# MDR32F8 register map
Vendor: Milandr; File version: 1.0
CPU: CM4 r1p1, little endian, no MPU, no FPU, 3 interrupt priority bits
Registers are 32-bit, read-write, reset 0x0 unless marked. A register's access mark holds for its fields unless they carry their own. Offsets are from the block's base; [hi:lo] are bit positions; {n}, {i} and the like mark numbered series.

## MDR_SSP — SSP interfase controller registers
Base 0x40095000; register names take the prefix MDR_SSP
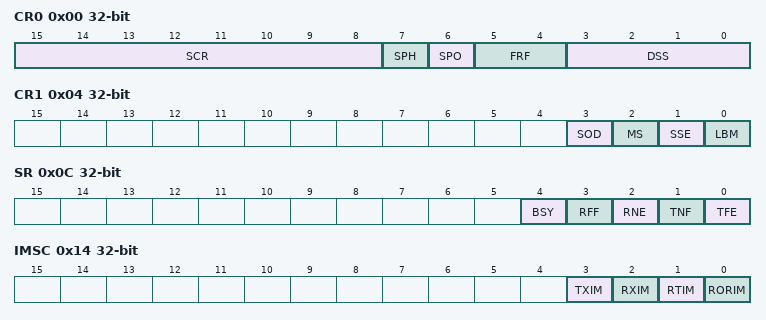
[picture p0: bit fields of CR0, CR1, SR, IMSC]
0x00 CR0 — SSP Control0 Register
  [15:8] SCR, [7] SPH, [6] SPO, [5:4] FRF, [3:0] DSS
0x04 CR1 — SSP Control1 Register
  [3] SOD, [2] MS, [1] SSE, [0] LBM
0x08 DR wo — SSP Data Register
  [15:0] DATA
0x0C SR ro — SSP Status Register
  [4] BSY, [3] RFF, [2] RNE, [1] TNF, [0] TFE
0x10 CPSR — SSP Clock Prescaler Register
  [7:0] CPSDVSR
0x14 IMSC — SSP Interrupt Mask Register
  [3] TXIM, [2] RXIM, [1] RTIM, [0] RORIM
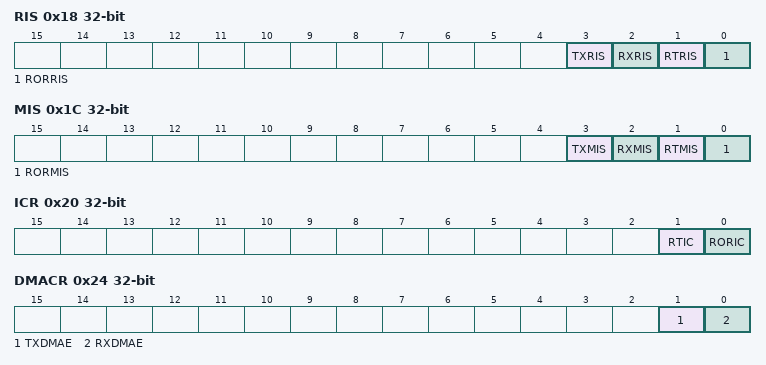
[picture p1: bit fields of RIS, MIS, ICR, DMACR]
0x18 RIS ro — SSP Interrupt Pending Register
  [3] TXRIS, [2] RXRIS, [1] RTRIS, [0] RORRIS
0x1C MIS ro — SSP Masked Interrupt Pending Register
  [3] TXMIS, [2] RXMIS, [1] RTMIS, [0] RORMIS
0x20 ICR — SSP Interrupt Clear Register
  [1] RTIC, [0] RORIC
0x24 DMACR — SSP DMA Control Register
  [1] TXDMAE, [0] RXDMAE

## UART0 — UART0 interfase controller registers
Base 0x40099000
Same registers: UART1 0x4009A000
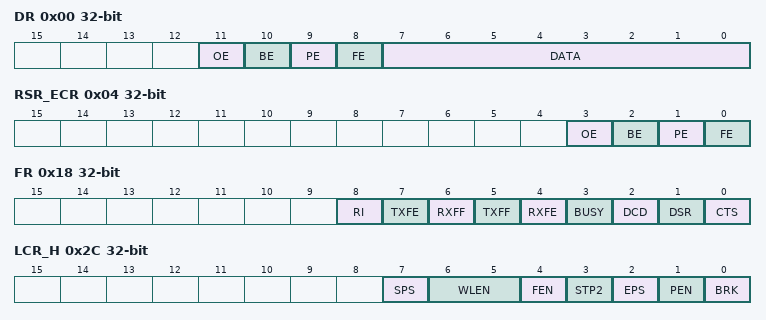
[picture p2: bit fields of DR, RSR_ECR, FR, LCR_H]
0x00 DR wo — UART Data Register
  [11] OE rw, [10] BE rw, [9] PE rw, [8] FE rw, [7:0] DATA
0x04 RSR_ECR — UART RSR Register
  [3] OE, [2] BE, [1] PE, [0] FE
0x18 FR ro — UART Flag Register
  [8] RI, [7] TXFE, [6] RXFF, [5] TXFF, [4] RXFE, [3] BUSY, [2] DCD, [1] DSR, [0] CTS
0x24 IBRD
  [15:0] BAUD_DIVINT
0x28 FBRD
  [5:0] BAUD_DIVFRAC
0x2C LCR_H — UART LCR_H Register
  [7] SPS, [6:5] WLEN, [4] FEN, [3] STP2, [2] EPS, [1] PEN, [0] BRK
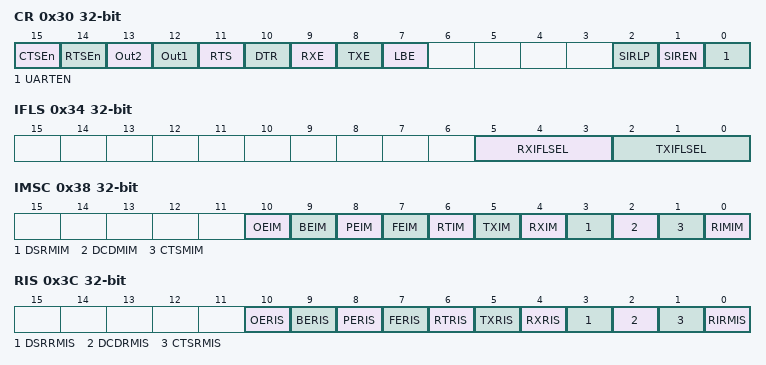
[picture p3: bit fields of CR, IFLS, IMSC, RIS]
0x30 CR — UART Command Register
  [15] CTSEn, [14] RTSEn, [13] Out2, [12] Out1, [11] RTS, [10] DTR, [9] RXE, [8] TXE, [7] LBE, [2] SIRLP, [1] SIREN, [0] UARTEN
0x34 IFLS — UART IFLS Register
  [5:3] RXIFLSEL, [2:0] TXIFLSEL
0x38 IMSC — UART Interrupt Mask Register
  [10] OEIM, [9] BEIM, [8] PEIM, [7] FEIM, [6] RTIM, [5] TXIM, [4] RXIM, [3] DSRMIM, [2] DCDMIM, [1] CTSMIM, [0] RIMIM
0x3C RIS ro — UART Interrupt Pending Register
  [10] OERIS, [9] BERIS, [8] PERIS, [7] FERIS, [6] RTRIS, [5] TXRIS, [4] RXRIS, [3] DSRRMIS, [2] DCDRMIS, [1] CTSRMIS, [0] RIRMIS
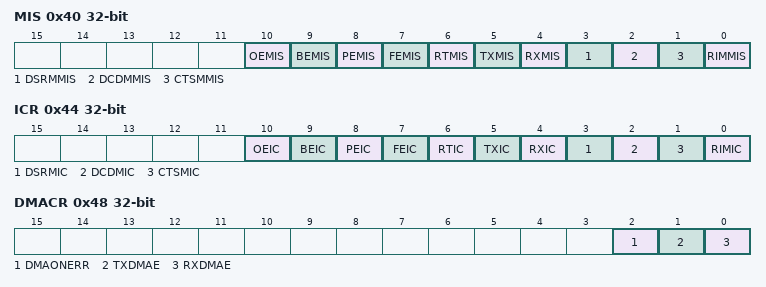
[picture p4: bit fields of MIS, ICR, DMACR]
0x40 MIS ro — UART Masked Interrupt Pending Register
  [10] OEMIS, [9] BEMIS, [8] PEMIS, [7] FEMIS, [6] RTMIS, [5] TXMIS, [4] RXMIS, [3] DSRMMIS, [2] DCDMMIS, [1] CTSMMIS, [0] RIMMIS
0x44 ICR wo — UART Interrupt Clear Register
  [10] OEIC, [9] BEIC, [8] PEIC, [7] FEIC, [6] RTIC, [5] TXIC, [4] RXIC, [3] DSRMIC, [2] DCDMIC, [1] CTSMIC, [0] RIMIC
0x48 DMACR — UART DMA Control Register
  [2] DMAONERR, [1] TXDMAE, [0] RXDMAE
{0xFE0+4i} PerlID{i} ro (reset mask 0xFF) (i=0..7) — PerlID0 UART Register

## ARINC429R — ARINC429 Receive Controller
Base 0x4009E000
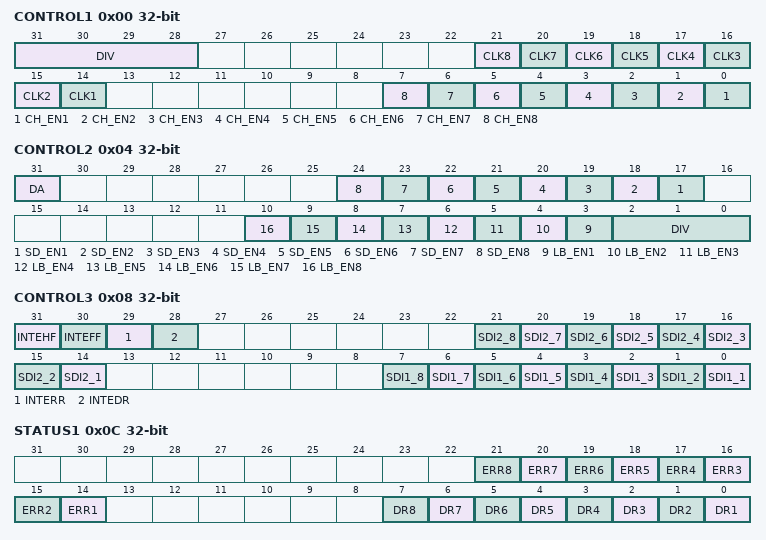
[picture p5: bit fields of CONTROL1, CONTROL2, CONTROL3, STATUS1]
0x00 CONTROL1 — ARINC429R Control1 register
  [31:28] DIV, [n+13] CLK{n} (n=1..8), [n-1] CH_EN{n} (n=1..8)
0x04 CONTROL2 — ARINC429R Control2 register
  [31] DA, [n+16] SD_EN{n} (n=1..8), [n+2] LB_EN{n} (n=1..8), [2:0] DIV
0x08 CONTROL3 — ARINC429R Control3 register
  [31] INTEHF, [30] INTEFF, [29] INTERR, [28] INTEDR, [n+13] SDI2_{n} (n=1..8), [n-1] SDI1_{n} (n=1..8)
0x0C STATUS1 — ARINC429R Status 1 register
  [n+13] ERR{n} (n=1..8), [n-1] DR{n} (n=1..8)
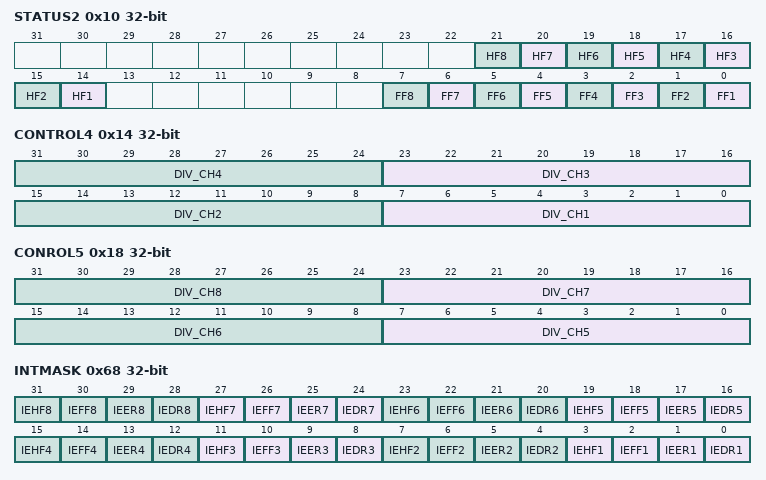
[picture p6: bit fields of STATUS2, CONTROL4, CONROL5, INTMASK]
0x10 STATUS2 — ARINC429R Status 2 register
  [n+13] HF{n} (n=1..8), [n-1] FF{n} (n=1..8)
0x14 CONTROL4 — ARINC429R Control 4 register
  [8n-1:8n-8] DIV_CH{n} (n=1..4)
0x18 CONROL5 — ARINC429R Control 5 register
  [8n-33:8n-40] DIV_CH{n} (n=5..8)
0x1C CHANNEL — ARINC429R Channel register
  [3:0] CHAN
0x20 LABEL wo — ARINC429R LabeL register
0x24 DATA_R wo — ARINC429R Data_R register
{0x2C+4i} DATA_R{i} wo (i=1..8) — ARINC429R Data {i} register
0x68 INTMASK — ARINC429R interrupt mask register
  [4n-1] IEHF{n} (n=1..8), [4n-2] IEFF{n} (n=1..8), [4n-3] IEER{n} (n=1..8), [4n-4] IEDR{n} (n=1..8)
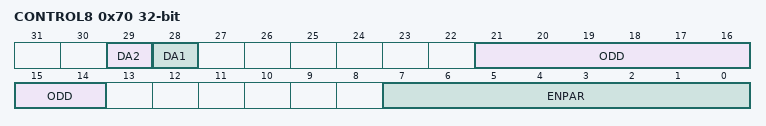
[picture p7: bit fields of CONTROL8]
0x70 CONTROL8 — ARINC429R CONTROL8 register
  [29] DA2, [28] DA1, [21:14] ODD, [7:0] ENPAR
0x74 CONTROL9 — ARINC429R CONTROL9 register
  [7:0] ENSYNC
